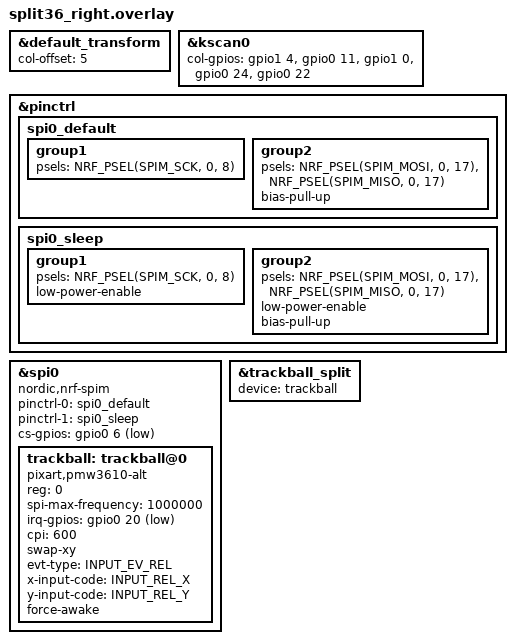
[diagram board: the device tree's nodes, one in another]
#include "split36.dtsi"

&default_transform {
    col-offset = <5>;
};

&kscan0 {
    col-gpios
        = <&gpio1 4 GPIO_ACTIVE_HIGH>
        , <&gpio0 11 GPIO_ACTIVE_HIGH>
        , <&gpio1 0 GPIO_ACTIVE_HIGH>
        , <&gpio0 24 GPIO_ACTIVE_HIGH>
        , <&gpio0 22 GPIO_ACTIVE_HIGH>
        ;
};

&pinctrl {
    spi0_default: spi0_default {
        group1 {
            psels = <NRF_PSEL(SPIM_SCK, 0, 8)>;
        };
        group2 {
            psels = <NRF_PSEL(SPIM_MOSI, 0, 17)>,
                    <NRF_PSEL(SPIM_MISO, 0, 17)>;
            bias-pull-up;
        };
    };

    spi0_sleep: spi0_sleep {
        group1 {
            psels = <NRF_PSEL(SPIM_SCK, 0, 8)>;
            low-power-enable;
        };
        group2 {
            psels = <NRF_PSEL(SPIM_MOSI, 0, 17)>,
                    <NRF_PSEL(SPIM_MISO, 0, 17)>;
            low-power-enable;
            bias-pull-up;
        };
    };
};

#include <zephyr/dt-bindings/input/input-event-codes.h>

&spi0 {
    status = "okay";
    compatible = "nordic,nrf-spim";
    pinctrl-0 = <&spi0_default>;
    pinctrl-1 = <&spi0_sleep>;
    pinctrl-names = "default", "sleep";
    cs-gpios = <&gpio0 6 GPIO_ACTIVE_LOW>;

    trackball: trackball@0 {
        status = "okay";
        compatible = "pixart,pmw3610-alt";
        reg = <0>;
        spi-max-frequency = <1000000>;
        irq-gpios = <&gpio0 20 (GPIO_ACTIVE_LOW | GPIO_PULL_UP)>;
        cpi = <600>;
        swap-xy;
        evt-type = <INPUT_EV_REL>;
        x-input-code = <INPUT_REL_X>;
        y-input-code = <INPUT_REL_Y>;
        force-awake;
    };
};

&trackball_split {
        device = <&trackball>;
};

